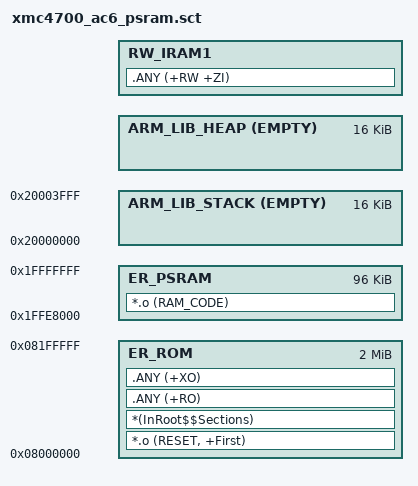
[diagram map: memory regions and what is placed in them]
#! armclang -E --target=arm-arm-none-eabi -mcpu=cortex-m4 -xc
/*
;-------- <<< Use Configuration Wizard in Context Menu >>> -------------------
*/

/*--------------------- Stack / Heap Configuration ---------------------------
; <h> Stack / Heap Configuration
;   <o0> Stack Size (in Bytes) <0x0-0xFFFFFFFF:8>
;   <o1> Heap Size (in Bytes) <0x0-0xFFFFFFFF:8>
;   <o2> gap between stack top and heap base (in Bytes) <0x0-0xFFFFFFFF:8>
;   <o3> gap between heap top and rw_zi base (in Bytes) <0x0-0xFFFFFFFF:8>
; </h>
 *----------------------------------------------------------------------------*/
#define __STACK_SIZE		0x00004000
#define __HEAP_SIZE			0x00004000
#define __STACK_HEAP_GAP	0x10
#define __HEAP_RW_GAP		0x10

#define __ROM_BASE     0x08000000
;#define __ROM_BASE     0x0C000000
#define __ROM_SIZE     0x00200000

#define __PSRAM_BASE   0x1FFE8000
#define __PSRAM_SIZE   0x00018000

#define __DSRAM_1_2_BASE  0x20000000
#define __DSRAM_1_2_SIZE  0x00040000

#define __STACK_TOP			(__DSRAM_1_2_BASE + __STACK_SIZE)
#define __HEAP_BASE			(AlignExpr(__STACK_TOP + __STACK_HEAP_GAP, 8))
#define __RWZI_BASE			(AlignExpr(__HEAP_BASE + __HEAP_SIZE + __HEAP_RW_GAP, 8))
#define __RWZI_SIZE			(AlignExpr(__DSRAM_1_2_SIZE - __STACK_SIZE - __STACK_HEAP_GAP - __HEAP_SIZE - __HEAP_RW_GAP, 8))

#define __RO_BASE         __ROM_BASE
#define __RO_SIZE         __ROM_SIZE
#define __NO_INIT         0x40

LR_ROM __RO_BASE __RO_SIZE  {
  ER_ROM __RO_BASE __RO_SIZE  {
   *.o (RESET, +First)
   *(InRoot$$Sections)
   .ANY (+RO)
   .ANY (+XO)
  }

  ER_PSRAM __PSRAM_BASE __PSRAM_SIZE {
    *.o (RAM_CODE)                                ; Matches explicit section name from attributes
  }
  
  ARM_LIB_STACK __STACK_TOP EMPTY -__STACK_SIZE {
  }

  ARM_LIB_HEAP  __HEAP_BASE EMPTY  __HEAP_SIZE {
  }

  RW_IRAM1 __RWZI_BASE (__RWZI_SIZE - __NO_INIT)  {
   .ANY (+RW +ZI)
  }
}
